# STM32WB30_CM4 register map
File version: 1.4-IAR
CPU: CM4 r0p1, little endian, MPU, FPU, 4 interrupt priority bits
Registers are 32-bit, read-write, reset 0x0 unless marked. A register's access mark holds for its fields unless they carry their own. Offsets are from the block's base; [hi:lo] are bit positions; {n}, {i} and the like mark numbered series; 'fields as' and 'values as' point back to an identical list.

## SYSCFG — System configuration controller
Base 0x40010000
0x00 MEMRMP — memory remap register
  [2:0] MEM_MODE — Memory mapping selection
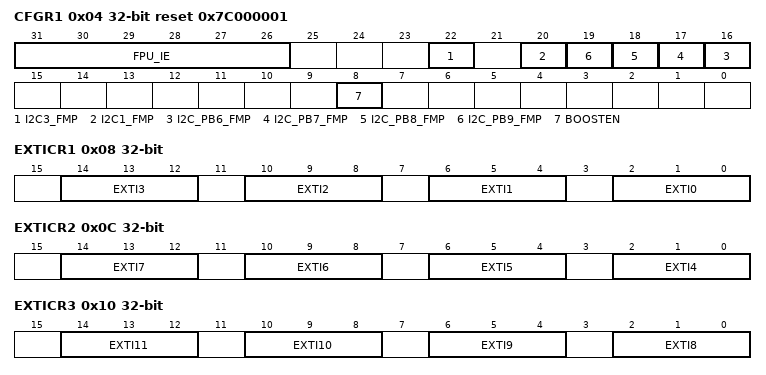
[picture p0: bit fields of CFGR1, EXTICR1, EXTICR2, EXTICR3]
0x04 CFGR1 reset 0x7C000001 — configuration register 1
  [31:26] FPU_IE — Floating Point Unit interrupts enable bits
  [22] I2C3_FMP — I2C3 Fast-mode Plus driving capability activation
  [20] I2C1_FMP — I2C1 Fast-mode Plus driving capability activation
  [n+10] I2C_PB{n}_FMP (n=6..9) — Fast-mode Plus (Fm+) driving capability activation on PB{n}
  [8] BOOSTEN — I/O analog switch voltage booster enable
0x08 EXTICR1 — external interrupt configuration register 1
  [4n+2:4n] EXTI{n} (n=0..3) — EXTI {n} configuration bits
0x0C EXTICR2 — external interrupt configuration register 2
  [4n-14:4n-16] EXTI{n} (n=4..7) — EXTI {n} configuration bits
0x10 EXTICR3 — external interrupt configuration register 3
  [4n-30:4n-32] EXTI{n} (n=8..11) — EXTI {n} configuration bits
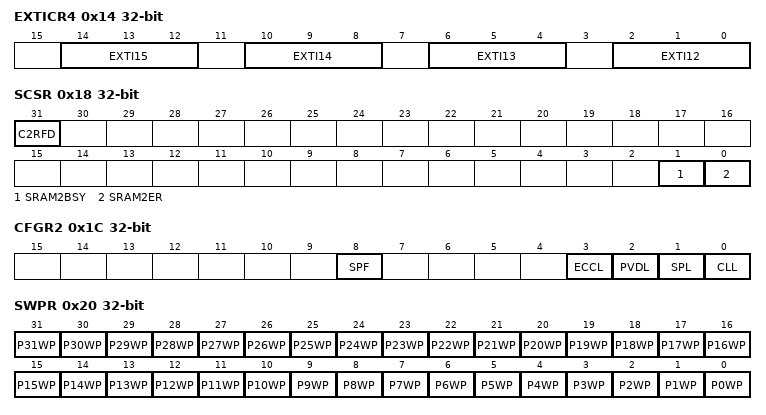
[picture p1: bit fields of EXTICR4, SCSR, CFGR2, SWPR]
0x14 EXTICR4 — external interrupt configuration register 4
  [4n-46:4n-48] EXTI{n} (n=12..15) — EXTI{n} configuration bits
0x18 SCSR access per field
  [31] C2RFD rw — CPU2 SRAM fetch (execution) disable.
  [1] SRAM2BSY ro — SRAM2 busy by erase operation
  [0] SRAM2ER rw — SRAM2 Erase
0x1C CFGR2 access per field
  [8] SPF rw — SRAM2 parity error flag
  [3] ECCL wo — ECC Lock
  [2] PVDL wo — PVD lock enable bit
  [1] SPL wo — SRAM2 parity lock bit
  [0] CLL wo — Cortex-M4 LOCKUP (Hardfault) output enable bit
0x20 SWPR wo — SRAM2 write protection register
  [31] P31WP — SRAM2 page 31 write protection
  [n] P{n}WP (n=0..30)
0x24 SKR wo
  [7:0] KEY — SRAM2 write protection key for software erase
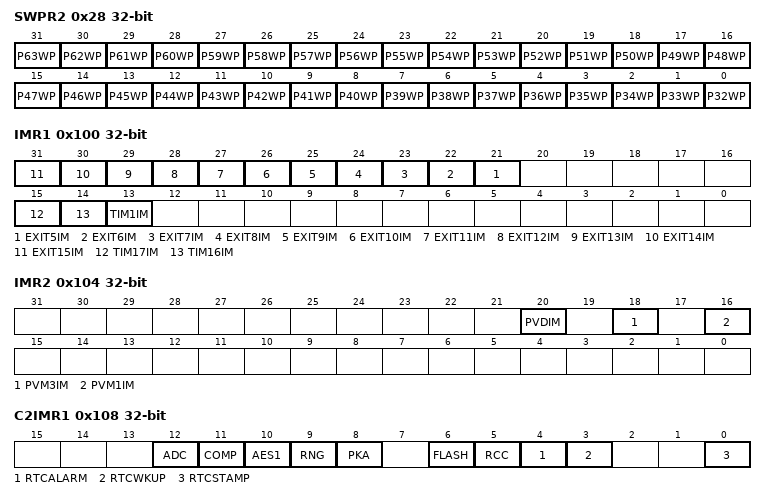
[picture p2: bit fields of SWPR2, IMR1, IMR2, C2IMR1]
0x28 SWPR2 wo — SRAM2 write protection register 2
  [31] P63WP — SRAM2 page 63 write protection
  [n-32] P{n}WP (n=32..62)
0x100 IMR1 — CPU1 interrupt mask register 1
  [n+16] EXIT{n}IM (n=5..15) — Peripheral EXIT{n} interrupt mask to CPU1
  [15] TIM17IM — Peripheral TIM17 interrupt mask to CPU1
  [14] TIM16IM — Peripheral TIM16 interrupt mask to CPU1
  [13] TIM1IM — Peripheral TIM1 interrupt mask to CPU1
0x104 IMR2 — CPU1 interrupt mask register 2
  [20] PVDIM — Peripheral PVD interrupt mask to CPU1
  [18] PVM3IM — Peripheral PVM3 interrupt mask to CPU1
  [16] PVM1IM — Peripheral PVM1 interrupt mask to CPU1
0x108 C2IMR1 — CPU2 interrupt mask register 1
  [12] ADC — Peripheral ADC interrupt mask to CPU2
  [11] COMP — Peripheral COMP interrupt mask to CPU2
  [10] AES1 — Peripheral AES1 interrupt mask to CPU2
  [9] RNG — Peripheral RNG interrupt mask to CPU2
  [8] PKA — Peripheral PKA interrupt mask to CPU2
  [6] FLASH — Peripheral FLASH interrupt mask to CPU2
  [5] RCC — Peripheral RCC interrupt mask to CPU2
  [4] RTCALARM — Peripheral RTCALARM interrupt mask to CPU2
  [3] RTCWKUP — Peripheral RTCWKUP interrupt mask to CPU2
  [0] RTCSTAMP — Peripheral RTCSTAMP interrupt mask to CPU2
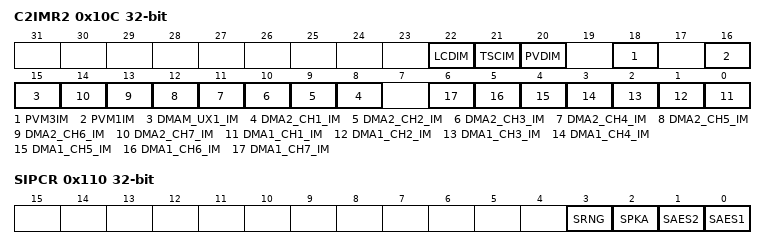
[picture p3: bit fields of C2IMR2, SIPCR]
0x10C C2IMR2 — CPU2 interrupt mask register 1
  [22] LCDIM — Peripheral LCDIM interrupt mask to CPU1
  [21] TSCIM — Peripheral TSCIM interrupt mask to CPU1
  [20] PVDIM — Peripheral PVDIM interrupt mask to CPU1
  [18] PVM3IM — Peripheral PVM3IM interrupt mask to CPU1
  [16] PVM1IM — Peripheral PVM1IM interrupt mask to CPU1
  [15] DMAM_UX1_IM — Peripheral DMAM UX1 interrupt mask to CPU1
  [n+7] DMA2_CH{n}_IM (n=1..7) — Peripheral DMA2 CH{n} interrupt mask to CPU1
  [n-1] DMA1_CH{n}_IM (n=1..7) — Peripheral DMA1 CH{n} interrupt mask to CPU2
0x110 SIPCR — secure IP control register
  [3] SRNG — Enable True RNG security
  [2] SPKA — Enable PKA security
  [1] SAES2 — Enable AES2 security.
  [0] SAES1 — Enable AES1 KEY[7:0] security.

## TIM16 — General purpose timers
Base 0x40014400
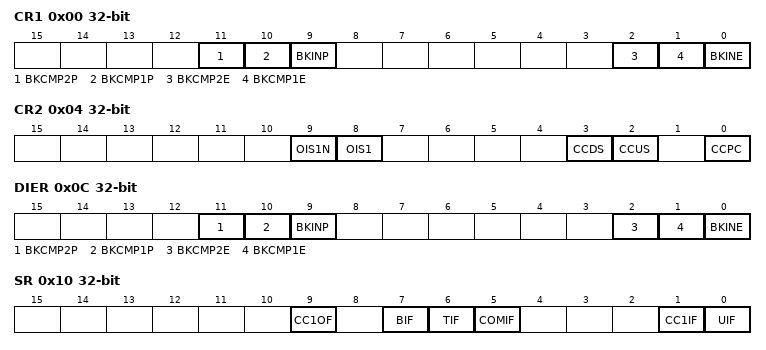
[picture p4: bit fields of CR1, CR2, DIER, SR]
0x00 CR1 — control register 1
  [11] BKCMP2P — BRK COMP2 input polarit
  [10] BKCMP1P — BRK COMP1 input polarity
  [9] BKINP — BRK BKIN input polarity
  [2] BKCMP2E — BRK COMP2 enable
  [1] BKCMP1E — BRK COMP1 enable
  [0] BKINE — BRK BKIN input enable
0x04 CR2 — control register 2
  [9] OIS1N — Output Idle state 1
  [8] OIS1 — Output Idle state 1
  [3] CCDS — Capture/compare DMA selection
  [2] CCUS — Capture/compare control update selection
  [0] CCPC — Capture/compare preloaded control
0x0C DIER — DMA/Interrupt enable register
  fields as CR1
0x10 SR — status register
  [9] CC1OF — Capture/Compare 1 overcapture flag
  [7] BIF — Break interrupt flag
  [6] TIF — Trigger interrupt flag
  [5] COMIF — COM interrupt flag
  [1] CC1IF — Capture/compare 1 interrupt flag
  [0] UIF — Update interrupt flag
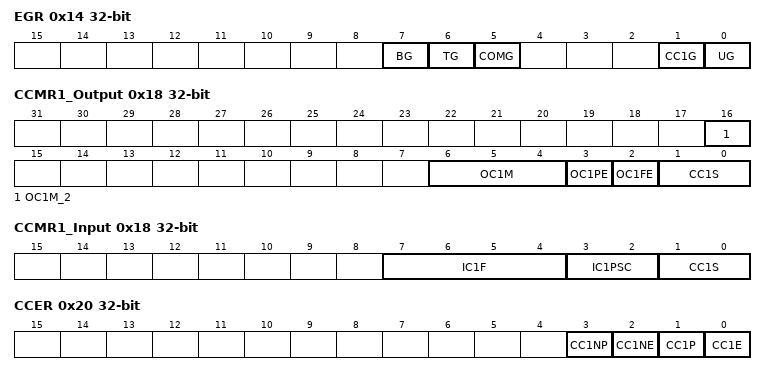
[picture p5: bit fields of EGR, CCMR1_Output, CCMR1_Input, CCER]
0x14 EGR wo — event generation register
  [7] BG — Break generation
  [6] TG — Trigger generation
  [5] COMG — Capture/Compare control update generation
  [1] CC1G — Capture/compare 1 generation
  [0] UG — Update generation
0x18 CCMR1_Output — capture/compare mode register (output mode)
  [16] OC1M_2 — Output Compare 1 mode
  [6:4] OC1M — Output Compare 1 mode
  [3] OC1PE — Output Compare 1 preload enable
  [2] OC1FE — Output Compare 1 fast enable
  [1:0] CC1S — Capture/Compare 1 selection
0x18 CCMR1_Input (alternate view of CCMR1_Output) — capture/compare mode register 1 (input mode)
  [7:4] IC1F — Input capture 1 filter
  [3:2] IC1PSC — Input capture 1 prescaler
  [1:0] CC1S — Capture/Compare 1 selection
0x20 CCER — capture/compare enable register
  [3] CC1NP — Capture/Compare 1 output Polarity
  [2] CC1NE — Capture/Compare 1 complementary output enable
  [1] CC1P — Capture/Compare 1 output Polarity
  [0] CC1E — Capture/Compare 1 output enable
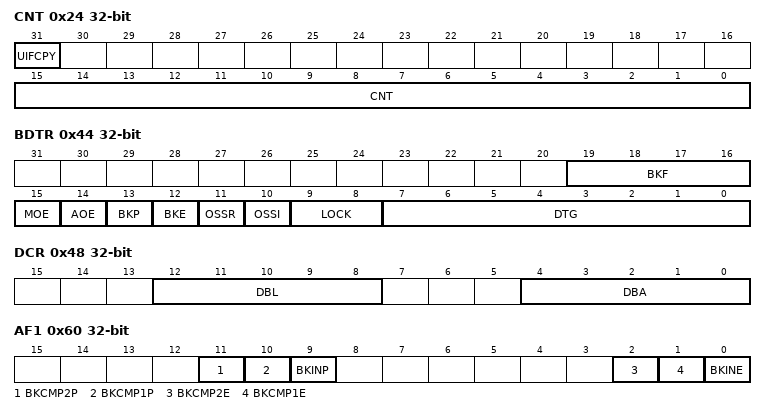
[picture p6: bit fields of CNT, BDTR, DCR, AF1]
0x24 CNT access per field — counter
  [31] UIFCPY ro — UIF Copy
  [15:0] CNT rw — counter value
0x28 PSC — prescaler
  [15:0] PSC — Prescaler value
0x2C ARR — auto-reload register
  [15:0] ARR — Auto-reload value
0x30 RCR — repetition counter register
  [7:0] REP — Repetition counter value
0x34 CCR1 — capture/compare register 1
  [15:0] CCR1 — Capture/Compare 1 value
0x44 BDTR — break and dead-time register
  [19:16] BKF — Break filter
  [15] MOE — Main output enable
  [14] AOE — Automatic output enable
  [13] BKP — Break polarity
  [12] BKE — Break enable
  [11] OSSR — Off-state selection for Run mode
  [10] OSSI — Off-state selection for Idle mode
  [9:8] LOCK — Lock configuration
  [7:0] DTG — Dead-time generator setup
0x48 DCR — DMA control register
  [12:8] DBL — DMA burst length
  [4:0] DBA — DMA base address
0x4C DMAR — DMA address for full transfer
  [15:0] DMAB — DMA register for burst accesses
0x50 OR — TIM16 option register 1
  [1:0] TI1_RMP — Input capture 1 remap
0x60 AF1 — TIM17 option register 1
  fields as CR1

## TIM17 — General purpose timers
Base 0x40014800
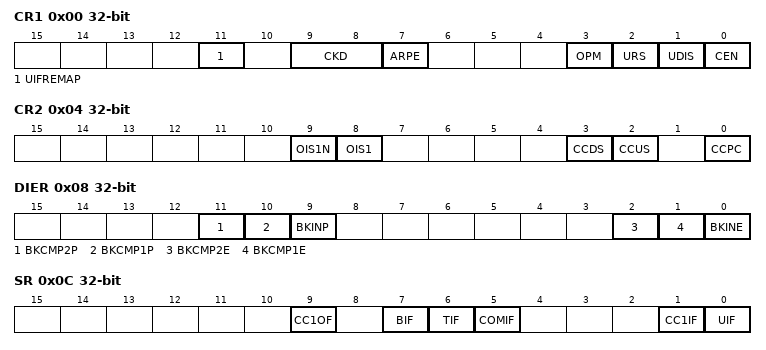
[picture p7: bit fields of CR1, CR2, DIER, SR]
0x00 CR1 — control register 1
  [11] UIFREMAP — UIF status bit remapping
  [9:8] CKD — Clock division
  [7] ARPE — Auto-reload preload enable
  [3] OPM — One-pulse mode
  [2] URS — Update request source
  [1] UDIS — Update disable
  [0] CEN — Counter enable
0x04 CR2 — control register 2
  [9] OIS1N — Output Idle state 1
  [8] OIS1 — Output Idle state 1
  [3] CCDS — Capture/compare DMA selection
  [2] CCUS — Capture/compare control update selection
  [0] CCPC — Capture/compare preloaded control
0x08 DIER — DMA/Interrupt enable register
  [11] BKCMP2P — BRK COMP2 input polarit
  [10] BKCMP1P — BRK COMP1 input polarity
  [9] BKINP — BRK BKIN input polarity
  [2] BKCMP2E — BRK COMP2 enable
  [1] BKCMP1E — BRK COMP1 enable
  [0] BKINE — BRK BKIN input enable
0x0C SR — status register
  [9] CC1OF — Capture/Compare 1 overcapture flag
  [7] BIF — Break interrupt flag
  [6] TIF — Trigger interrupt flag
  [5] COMIF — COM interrupt flag
  [1] CC1IF — Capture/compare 1 interrupt flag
  [0] UIF — Update interrupt flag
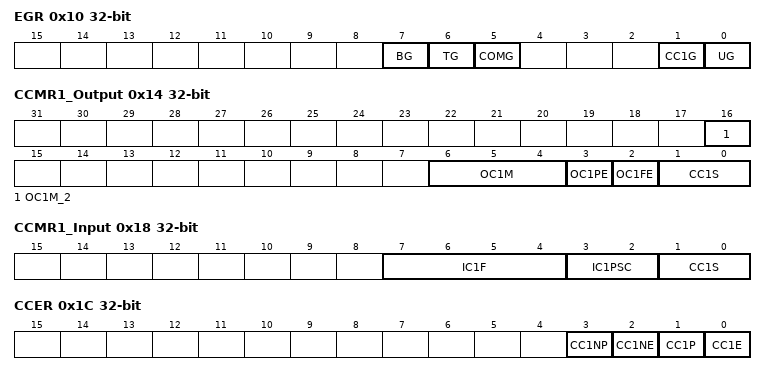
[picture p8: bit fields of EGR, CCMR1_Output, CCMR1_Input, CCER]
0x10 EGR wo — event generation register
  [7] BG — Break generation
  [6] TG — Trigger generation
  [5] COMG — Capture/Compare control update generation
  [1] CC1G — Capture/compare 1 generation
  [0] UG — Update generation
0x14 CCMR1_Output — capture/compare mode register (output mode)
  [16] OC1M_2 — Output Compare 1 mode
  [6:4] OC1M — Output Compare 1 mode
  [3] OC1PE — Output Compare 1 preload enable
  [2] OC1FE — Output Compare 1 fast enable
  [1:0] CC1S — Capture/Compare 1 selection
0x18 CCMR1_Input — capture/compare mode register 1 (input mode)
  [7:4] IC1F — Input capture 1 filter
  [3:2] IC1PSC — Input capture 1 prescaler
  [1:0] CC1S — Capture/Compare 1 selection
0x1C CCER — capture/compare enable register
  [3] CC1NP — Capture/Compare 1 output Polarity
  [2] CC1NE — Capture/Compare 1 complementary output enable
  [1] CC1P — Capture/Compare 1 output Polarity
  [0] CC1E — Capture/Compare 1 output enable
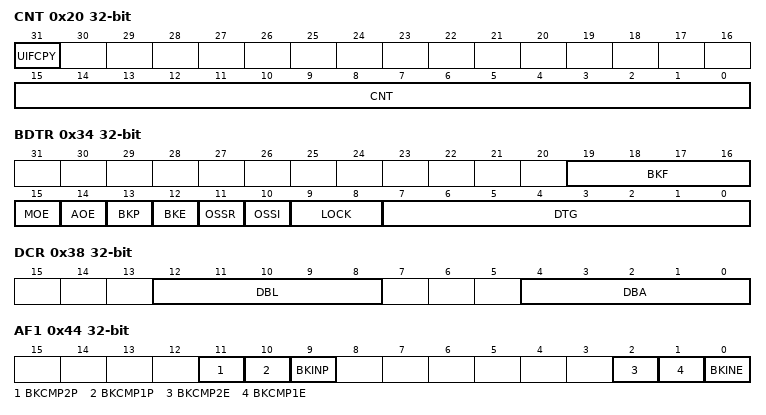
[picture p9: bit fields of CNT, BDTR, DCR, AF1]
0x20 CNT access per field — counter
  [31] UIFCPY ro — UIF Copy
  [15:0] CNT rw — counter value
0x24 PSC — prescaler
  [15:0] PSC — Prescaler value
0x28 ARR — auto-reload register
  [15:0] ARR — Auto-reload value
0x2C RCR — repetition counter register
  [7:0] REP — Repetition counter value
0x30 CCR1 — capture/compare register 1
  [15:0] CCR1 — Capture/Compare 1 value
0x34 BDTR — break and dead-time register
  [19:16] BKF — Break filter
  [15] MOE — Main output enable
  [14] AOE — Automatic output enable
  [13] BKP — Break polarity
  [12] BKE — Break enable
  [11] OSSR — Off-state selection for Run mode
  [10] OSSI — Off-state selection for Idle mode
  [9:8] LOCK — Lock configuration
  [7:0] DTG — Dead-time generator setup
0x38 DCR — DMA control register
  [12:8] DBL — DMA burst length
  [4:0] DBA — DMA base address
0x3C DMAR — DMA address for full transfer
  [15:0] DMAB — DMA register for burst accesses
0x40 OR — TIM16 option register 1
  [1:0] TI1_RMP — Input capture 1 remap
0x44 AF1 — TIM17 option register 1
  fields as DIER

## WWDG — System window watchdog
Base 0x40002C00
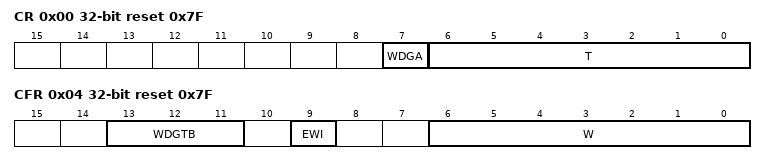
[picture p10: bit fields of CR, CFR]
0x00 CR reset 0x7F — Control register
  [7] WDGA — Activation bit
  [6:0] T — 7-bit counter (MSB to LSB)
0x04 CFR reset 0x7F — Configuration register
  [13:11] WDGTB — Timer base
  [9] EWI — Early wakeup interrupt
  [6:0] W — 7-bit window value
0x08 SR — Status register
  [0] EWIF — Early wakeup interrupt flag
